VERSION ""

NS_ :

BS_:

BU_: VIST DDSS SCM_1
VAL_TABLE_ welcome 3 "Description for the value '0x3'" 2 "Description for the value '0x2'" 1 "on" 0 "off" ;
VAL_TABLE_ conference_Mode 3 "Description for the value '0x3'" 2 "Description for the value '0x2'" 1 "on" 0 "off" ;
VAL_TABLE_ fatigue 7 "Description for the value '0x7'" 6 "Description for the value '0x6'" 5 "Description for the value '0x5'" 4 "Description for the value '0x4'" 3 "severe" 2 "Moderate" 1 "mild" 0 "normal" ;
VAL_TABLE_ autopilot 3 "Description for the value '0x3'" 2 "Description for the value '0x2'" 1 "ON" 0 "OFF" ;
VAL_TABLE_ Scene_Mode 7 "res" 6 "res" 5 "Sleep" 4 "OFF" 3 "Movie" 2 "OFF" 1 "Pre_meal" 0 "OFF" ;

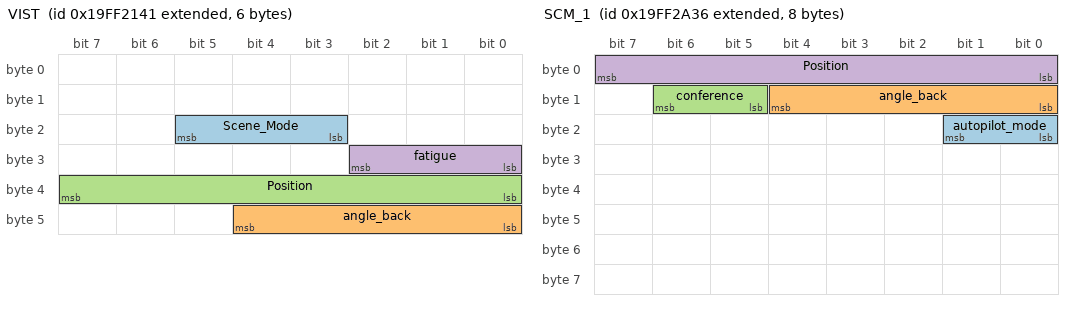
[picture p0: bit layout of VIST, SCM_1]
BO_ 2583634241 VIST: 6 Vector__XXX
 SG_ Scene_Mode : 19|3@1+ (1,0) [0|7] "" Vector__XXX
 SG_ angle_back : 40|5@1+ (1,0) [0|31] "" Vector__XXX
 SG_ Position : 32|8@1+ (1,0) [0|255] "" Vector__XXX
 SG_ fatigue : 24|3@1+ (1,0) [0|7] ""  SCM_1

BO_ 2583635362 DDSS: 8 Vector__XXX
 SG_ welcome_state1 : 0|2@1+ (1,0) [0|3] ""  SCM_1

BO_ 2583636534 SCM_1: 8 SCM_1
 SG_ autopilot_mode : 16|2@1+ (1,0) [0|3] "" Vector__XXX
 SG_ angle_back : 8|5@1+ (1,0) [0|31] "" Vector__XXX
 SG_ conference : 13|2@1+ (1,0) [0|3] "" Vector__XXX
 SG_ Position : 0|8@1+ (1,0) [0|255] "" Vector__XXX

CM_ " ";
BA_DEF_ BO_  "GenMsgSendType" ENUM  "cyclic","Event","IfActive","CE","CA","NoMsgSendType";
BA_DEF_ SG_  "GenSigSendType" ENUM  "cyclic","OnChange","OnWrite","IfActive","OnChangeWithRepetition","OnWriteWithRepetition","IfActiveWithRepetition","NoSigSendType","OnChangeAndIfActive","OnChangeAndIfActiveWithRepetition","CA","CE","Event";
BA_DEF_  "DBName" STRING ;
BA_DEF_  "NmBaseAddress" HEX 1024 1087;
BA_DEF_ SG_  "GenSigISendType" ENUM  "Cycle";
BA_DEF_ BO_  "GenMsgILSupport" ENUM  "no","yes";
BA_DEF_  "BusType" STRING ;
BA_DEF_ BU_  "NodeLayerModules" STRING ;
BA_DEF_DEF_  "GenMsgSendType" "cyclic";
BA_DEF_DEF_  "GenSigSendType" "cyclic";
BA_DEF_DEF_  "DBName" "";
BA_DEF_DEF_  "NmBaseAddress" 1087;
BA_DEF_DEF_  "GenSigISendType" "Cycle";
BA_DEF_DEF_  "GenMsgILSupport" "yes";
BA_DEF_DEF_  "BusType" "";
BA_DEF_DEF_  "NodeLayerModules" "CANoeILNLV";
BA_ "BusType" "CAN";
BA_ "DBName" "X95CAN3";
VAL_ 2583634241 Scene_Mode 7 "res" 6 "res" 5 "Sleep" 4 "OFF" 3 "Movie" 2 "OFF" 1 "Pre_meal" 0 "OFF" ;
VAL_ 2583634241 fatigue 7 "Description for the value '0x7'" 6 "Description for the value '0x6'" 5 "Description for the value '0x5'" 4 "Description for the value '0x4'" 3 "severe" 2 "Moderate" 1 "mild" 0 "normal" ;
VAL_ 2583635362 welcome_state1 3 "Description for the value '0x3'" 2 "Description for the value '0x2'" 1 "on" 0 "off" ;
VAL_ 2583636534 autopilot_mode 3 "Description for the value '0x3'" 2 "Description for the value '0x2'" 1 "on" 0 "off" ;
VAL_ 2583636534 conference 3 "Description for the value '0x3'" 2 "Description for the value '0x2'" 1 "on" 0 "off" ;
